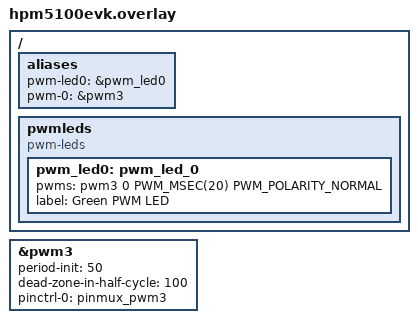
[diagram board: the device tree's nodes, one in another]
/*
 * Copyright 2026 HPMicro
 * SPDX-License-Identifier: Apache-2.0
 */

#include <zephyr/dt-bindings/pwm/pwm.h>

/ {
	aliases {
		pwm-led0 = &pwm_led0;
		pwm-0 = &pwm3;
	};

	pwmleds {
		compatible = "pwm-leds";
		pwm_led0: pwm_led_0 {
			pwms = <&pwm3 0 PWM_MSEC(20) PWM_POLARITY_NORMAL>;
			label = "Green PWM LED";
			status = "okay";
		};
	};
};

&pwm3 {
	status = "okay";
	period-init = <50>;
	dead-zone-in-half-cycle = <100>;
	pinctrl-0 = <&pinmux_pwm3>;
	pinctrl-names = "default";
};
